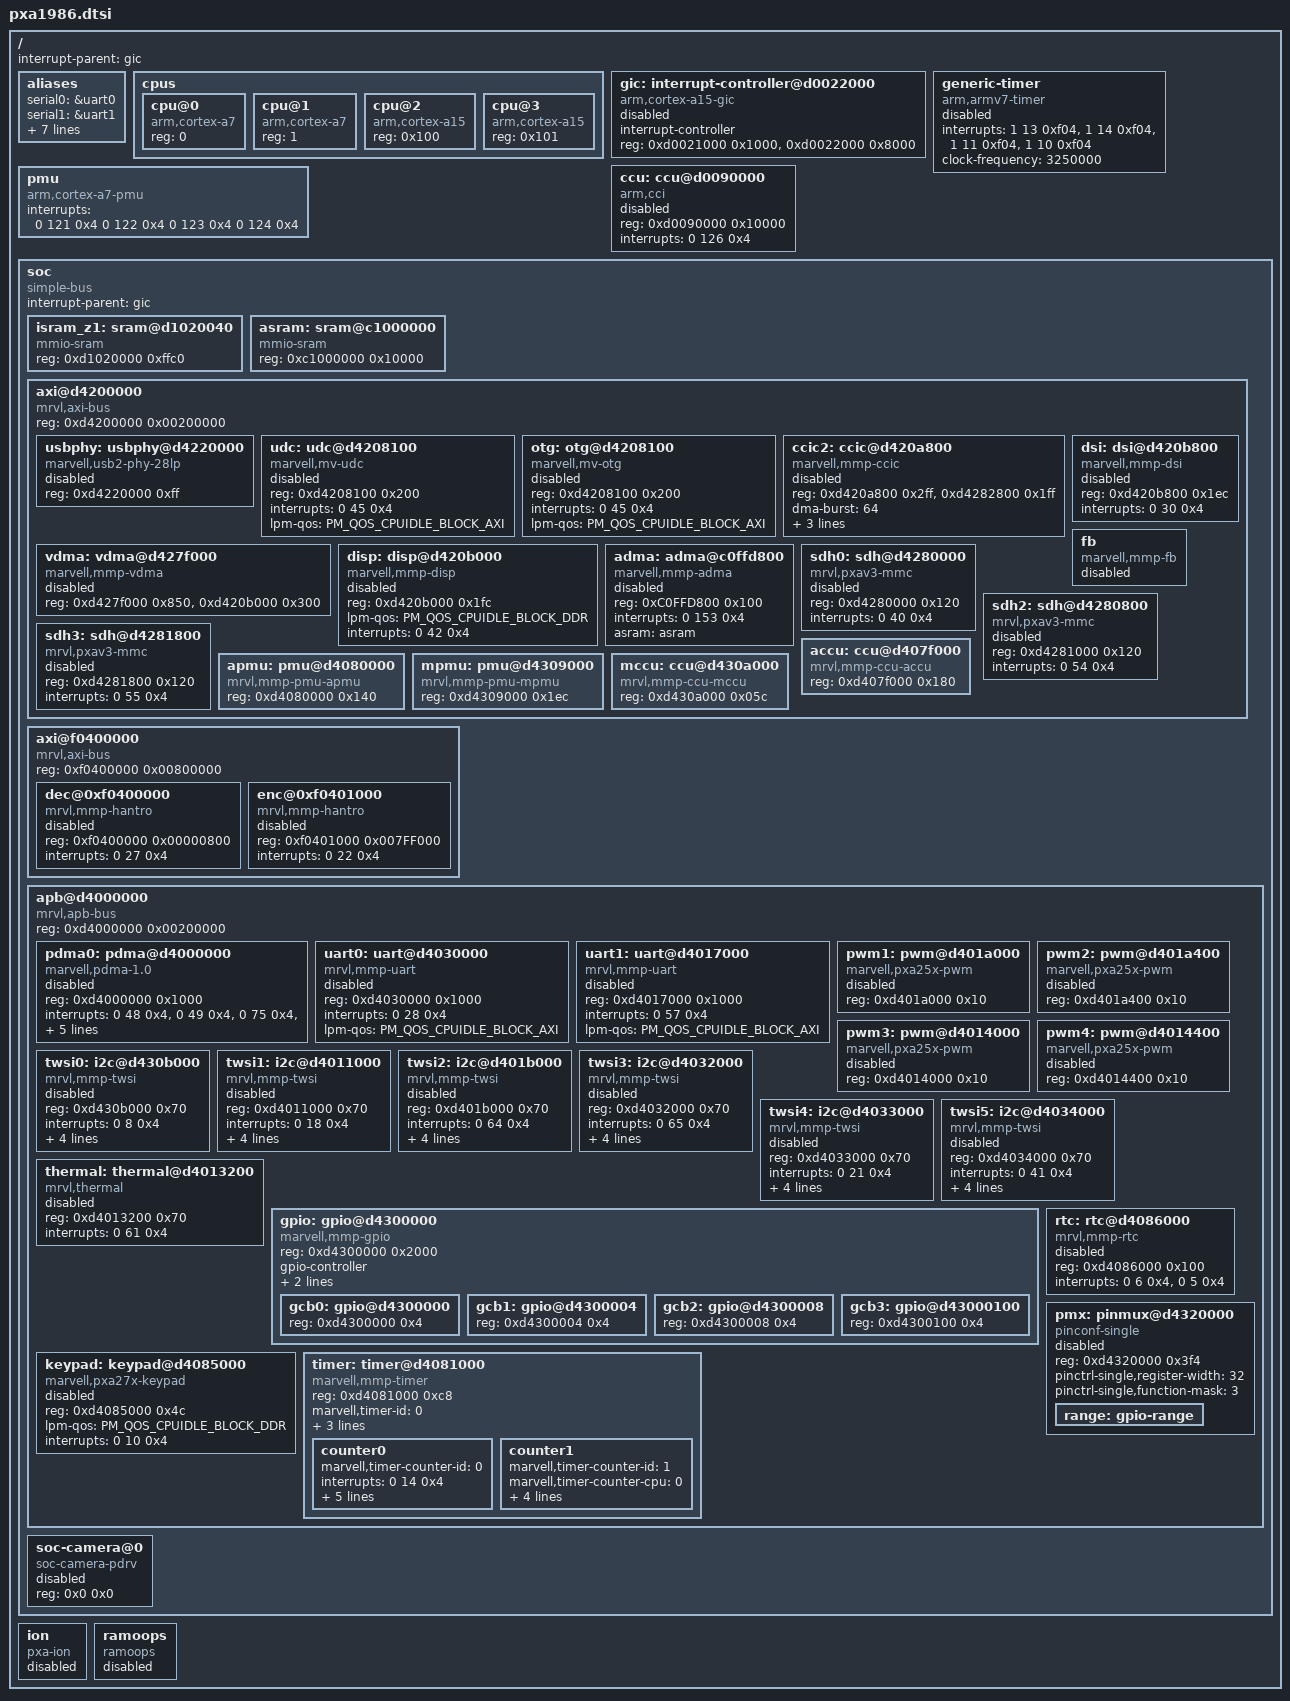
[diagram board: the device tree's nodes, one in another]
/*
 *  Copyright (C) 2013 Marvell Technology Group Ltd.
 *  Author: Chao Xie <chao.xie@marvell.com>
 *
 *  This program is free software; you can redistribute it and/or modify
 *  it under the terms of the GNU General Public License version 2 as
 *  publishhed by the Free Software Foundation.
 */

#include "skeleton.dtsi"
#include "eden-pinfunc.h"
#include "eden-pm.h"
#include <dt-bindings/interrupt-controller/irq.h>
#include <dt-bindings/usb/mv_usb_phy.h>

/ {
	interrupt-parent = <&gic>;

	aliases {
		serial0 = &uart0;
		serial1 = &uart1;
		i2c0 = &twsi0;
		i2c1 = &twsi1;
		i2c2 = &twsi2;
		i2c3 = &twsi3;
		i2c4 = &twsi4;
		i2c5 = &twsi5;
		mmp-camera1 = &ccic2;
	};

	cpus {
		#address-cells = <1>;
		#size-cells = <0>;

		cpu@0 {
			device_type = "cpu";
			compatible = "arm,cortex-a7";
			reg = <0>;
		};
		cpu@1 {
			device_type = "cpu";
			compatible = "arm,cortex-a7";
			reg = <1>;
		};
		cpu@2 {
			device_type = "cpu";
			compatible = "arm,cortex-a15";
			reg = <0x100>;
		};
		cpu@3 {
			device_type = "cpu";
			compatible = "arm,cortex-a15";
			reg = <0x101>;
		};
	};

	gic: interrupt-controller@d0022000 {
		compatible = "arm,cortex-a15-gic";
		interrupt-controller;
		#interrupt-cells = <3>;
		reg = <0xd0021000 0x1000>,
		      <0xd0022000 0x8000>;
		status = "disabled";
	};

	generic-timer {
		compatible = "arm,armv7-timer";
		/* PPI secure/nonsecure IRQ, active high level-sensitive */
		interrupts = <1 13 0xf04>,
					 <1 14 0xf04>,
					 <1 11 0xf04>,
					 <1 10 0xf04>;
		clock-frequency = <3250000>;
		status = "disabled";
	};

	ccu: ccu@d0090000 {
		compatible = "arm,cci";
		#address-cells = <1>;
		#size-cells = <1>;
		reg = <0xd0090000 0x10000>;
		interrupts = <0 126 0x4>;
		status = "disable";
	};

	pmu {
		compatible = "arm,cortex-a7-pmu";
		interrupts = <0 121 0x4
			      0 122 0x4
			      0 123 0x4
			      0 124 0x4>;
	};

	soc {
		#address-cells = <1>;
		#size-cells = <1>;
		compatible = "simple-bus";
		interrupt-parent = <&gic>;
		ranges;

		isram_z1: sram@d1020040 {
			compatible = "mmio-sram";
			reg = <0xd1020000 0xffc0>;	/* 64KB */
		};

		asram: sram@c1000000 {
			compatible = "mmio-sram";
			reg = <0xc1000000 0x10000>;	/* 64KB */
		};

		axi@d4200000 {	/* AXI */
			compatible = "mrvl,axi-bus", "simple-bus";
			#address-cells = <1>;
			#size-cells = <1>;
			reg = <0xd4200000 0x00200000>;
			ranges;

			usbphy: usbphy@d4220000 {
				compatible = "marvell,usb2-phy-28lp";
				reg = <0xd4220000 0xff>;
				status = "disabled";
			};

			udc: udc@d4208100 {
				compatible = "marvell,mv-udc";
				reg = <0xd4208100 0x200>;
				interrupts = <0 45 0x4>;
				lpm-qos = <PM_QOS_CPUIDLE_BLOCK_AXI>;
				status = "disabled";
			};

			otg: otg@d4208100 {
				compatible = "marvell,mv-otg";
				reg = <0xd4208100 0x200>;
				interrupts = <0 45 0x4>;
				lpm-qos = <PM_QOS_CPUIDLE_BLOCK_AXI>;
				status = "disabled";
			};

			ccic2: ccic@d420a800 {
				compatible = "marvell,mmp-ccic";
				reg = <0xd420a800 0x2ff>, <0xd4282800 0x1ff>;
				reg-names = "ccic-regs", "apmu-regs";
				dma-burst = <64>;
				mclk-src = <3>;
				mclk-div = <22>;
				interrupts = <0 43 0x4>;
				status = "disable";
			};

			dsi: dsi@d420b800 {
				compatible = "marvell,mmp-dsi";
				reg = <0xd420b800 0x1ec>;
				interrupts = <0 30 0x4>;
				status = "disabled";
			};

			vdma: vdma@d427f000 {
				compatible = "marvell,mmp-vdma";
				reg = <0xd427f000 0x850>, <0xd420b000 0x300>;
				status = "disabled";
			};

			disp: disp@d420b000 {
				compatible = "marvell,mmp-disp";
				reg = <0xd420b000 0x1fc>;
				lpm-qos = <PM_QOS_CPUIDLE_BLOCK_DDR>;
				interrupts = <0 42 0x4>;
				status = "disabled";
			};

			fb: fb {
				compatible = "marvell,mmp-fb";
				status = "disabled";
			};

/* FIXME */
			adma: adma@c0ffd800 {
				compatible = "marvell,mmp-adma";
				reg = <0xC0FFD800 0x100>;
				interrupts = <0 153 0x4>;
				#dma-cells = <1>;
				asram = <&asram>;
				status = "disabled";
			};

			sdh0: sdh@d4280000 {
					compatible = "mrvl,pxav3-mmc";
					reg = <0xd4280000 0x120>;
					interrupts = <0 40 0x4>;
					status = "disabled";
			 };

			sdh2: sdh@d4280800 {
					compatible = "mrvl,pxav3-mmc";
					reg = <0xd4281000 0x120>;
					interrupts = <0 54 0x4>;
					status = "disabled";
			};

			sdh3: sdh@d4281800 {
					compatible = "mrvl,pxav3-mmc";
					reg = <0xd4281800 0x120>;
					interrupts = <0 55 0x4>;
					status = "disabled";
			};

			apmu: pmu@d4080000 {
				compatible = "mrvl,mmp-pmu-apmu";
				reg = <0xd4080000 0x140>;
			};

			accu: ccu@d407f000 {
				compatible = "mrvl,mmp-ccu-accu";
				reg = <0xd407f000 0x180>;
			};

			mpmu: pmu@d4309000 {
				compatible = "mrvl,mmp-pmu-mpmu";
				reg = <0xd4309000 0x1ec>;
			};

			mccu: ccu@d430a000 {
				compatible = "mrvl,mmp-ccu-mccu";
				reg = <0xd430a000 0x05c>;
			};
		};

		axi@f0400000 {
			compatible = "mrvl,axi-bus", "simple-bus";
			#address-cells = <1>;
			#size-cells = <1>;
			reg = <0xf0400000 0x00800000>;
			ranges;

			dec@0xf0400000 {
				compatible = "mrvl,mmp-hantro";
				reg = <0xf0400000 0x00000800>;
				interrupts = <0 27 0x4>;
				status = "disabled";
			};

			enc@0xf0401000 {
				compatible = "mrvl,mmp-hantro";
				reg = <0xf0401000 0x007FF000>;
				interrupts = <0 22 0x4>;
				status = "disabled";
			};
		};

		apb@d4000000 {	/* APB */
			compatible = "mrvl,apb-bus", "simple-bus";
			#address-cells = <1>;
			#size-cells = <1>;
			reg = <0xd4000000 0x00200000>;
			ranges;

			pdma0: pdma@d4000000 {
				compatible = "marvell,pdma-1.0";
				reg = <0xd4000000 0x1000>;
				interrupts = <0 48 0x4>, <0 49 0x4>, <0 75 0x4>, <0 76 0x4>,
						<0 77 0x4>, <0 78 0x4>, <0 79 0x4>, <0 80 0x4>,
						<0 81 0x4>, <0 82 0x4>, <0 83 0x4>, <0 84 0x4>,
						<0 85 0x4>, <0 86 0x4>, <0 87 0x4>, <0 88 0x4>;
				#dma-cells= <2>;
				#dma-channels = <16>;
				status = "disabled";
			};

/* FIXME - enable when sound will be enabled */
#if 0
			sspa0: sspa@c0ffdc00 {
				compatible = "mrvl,mmp-sspa-dai";
				reg = <0xc0ffdc00 0x1000>;
				interrupts = <0 31 0x4>;
				dmas = <&adma 1
					&adma 0>;
				dma-names = "rx", "tx";
				asram = <&asram_z1>;
				platform_driver_name = "tdma_platform";
				status = "disabled";
			};
#endif

			uart0: uart@d4030000 {
				compatible = "mrvl,mmp-uart";
				reg = <0xd4030000 0x1000>;
				interrupts = <0 28 0x4>;
/* FIXME - no need pdma for now */
#if 0
				dmas = <&pdma0 0 1
					&pdma0 1 1>;
				dma-names = "rx", "tx";
#endif
				lpm-qos = <PM_QOS_CPUIDLE_BLOCK_AXI>;
				status = "disabled";
			};

			uart1: uart@d4017000 {
				compatible = "mrvl,mmp-uart";
				reg = <0xd4017000 0x1000>;
				interrupts = <0 57 0x4>;
/* FIXME - no need pdma for now */
#if 0
				dmas = <&pdma0 10 1
					&pdma0 11 1>;
				dma-names = "rx", "tx";
#endif
				lpm-qos = <PM_QOS_CPUIDLE_BLOCK_AXI>;
				status = "disabled";
			};

			pwm1: pwm@d401a000 {
				compatible = "marvell,pxa25x-pwm";
				reg = <0xd401a000 0x10>;
				#pwm-cells = <2>;
				status = "disabled";
			};

			pwm2: pwm@d401a400 {
				compatible = "marvell,pxa25x-pwm";
				reg = <0xd401a400 0x10>;
				#pwm-cells = <2>;
				status = "disabled";
			};

			pwm3: pwm@d4014000 {
				compatible = "marvell,pxa25x-pwm";
				reg = <0xd4014000 0x10>;
				#pwm-cells = <2>;
				status = "disabled";
			};

			pwm4: pwm@d4014400 {
				compatible = "marvell,pxa25x-pwm";
				reg = <0xd4014400 0x10>;
				#pwm-cells = <2>;
				status = "disabled";
			};

			twsi0: i2c@d430b000 {
				compatible = "mrvl,mmp-twsi";
				reg = <0xd430b000 0x70>;
				interrupts = <0 8 0x4>;
				#address-cells = <1>;
				#size-cells = <0>;
				lpm-qos = <PM_QOS_CPUIDLE_BLOCK_DDR>;
				mrvl,i2c-fast-mode;
				/*
				 *ilcr: fast mode b17~9=0x10, 400k
				 *      standard mode b8~0=0x9a, 100k
				 *iwcr: b5~0=b01010 recommended value from spec
				 */
				marvell,i2c-ilcr = <0x082C409a>;
				marvell,i2c-iwcr = <0x0000142a>;
				status = "disabled";
			};

			twsi1: i2c@d4011000 {
				compatible = "mrvl,mmp-twsi";
				reg = <0xd4011000 0x70>;
				interrupts = <0 18 0x4>;
				#address-cells = <1>;
				#size-cells = <0>;
				lpm-qos = <PM_QOS_CPUIDLE_BLOCK_DDR>;
				mrvl,i2c-fast-mode;
				marvell,i2c-ilcr = <0x082C489F>;
				marvell,i2c-iwcr = <0x0000142a>;
				status = "disabled";
			};

			twsi2: i2c@d401b000 {
				compatible = "mrvl,mmp-twsi";
				reg = <0xd401b000 0x70>;
				interrupts = <0 64 0x4>;
				#address-cells = <1>;
				#size-cells = <0>;
				lpm-qos = <PM_QOS_CPUIDLE_BLOCK_DDR>;
				mrvl,i2c-fast-mode;
				marvell,i2c-ilcr = <0x082C489F>;
				marvell,i2c-iwcr = <0x0000142a>;
				status = "disabled";
			};

			twsi3: i2c@d4032000 {
				compatible = "mrvl,mmp-twsi";
				reg = <0xd4032000 0x70>;
				interrupts = <0 65 0x4>;
				#address-cells = <1>;
				#size-cells = <0>;
				lpm-qos = <PM_QOS_CPUIDLE_BLOCK_DDR>;
				mrvl,i2c-fast-mode;
				marvell,i2c-ilcr = <0x082C489F>;
				marvell,i2c-iwcr = <0x0000142a>;
				status = "disabled";
			};

			twsi4: i2c@d4033000 {
				compatible = "mrvl,mmp-twsi";
				reg = <0xd4033000 0x70>;
				interrupts = <0 21 0x4>;
				#address-cells = <1>;
				#size-cells = <0>;
				lpm-qos = <PM_QOS_CPUIDLE_BLOCK_DDR>;
				mrvl,i2c-fast-mode;
				marvell,i2c-ilcr = <0x082C489F>;
				marvell,i2c-iwcr = <0x0000142a>;
				status = "disabled";
			};

			twsi5: i2c@d4034000 {
				compatible = "mrvl,mmp-twsi";
				reg = <0xd4034000 0x70>;
				interrupts = <0 41 0x4>;
				#address-cells = <1>;
				#size-cells = <0>;
				lpm-qos = <PM_QOS_CPUIDLE_BLOCK_DDR>;
				mrvl,i2c-fast-mode;
				marvell,i2c-ilcr = <0x082C489F>;
				marvell,i2c-iwcr = <0x0000142a>;
				status = "disabled";
			};

/* FIXME - add gpu thermals */
			thermal: thermal@d4013200 {
				compatible = "mrvl,thermal";
				reg = <0xd4013200 0x70>;
				interrupts = <0 61 0x4>;
				status = "disabled";
			};

			gpio: gpio@d4300000 {
				compatible = "marvell,mmp-gpio";
				#address-cells = <1>;
				#size-cells = <1>;
				reg = <0xd4300000 0x2000>;
				gpio-controller;
				#gpio-cells = <2>;
				interrupts = <0 24 0x4>;
				interrupt-names = "gpio_mux";
				interrupt-controller;
				#interrupt-cells = <2>;
				ranges;

				gcb0: gpio@d4300000 {
					reg = <0xd4300000 0x4>;
				};

				gcb1: gpio@d4300004 {
					reg = <0xd4300004 0x4>;
				};

				gcb2: gpio@d4300008 {
					reg = <0xd4300008 0x4>;
				};

				gcb3: gpio@d43000100 {
					reg = <0xd4300100 0x4>;
				};
			};

			keypad: keypad@d4085000 {
				compatible = "marvell,pxa27x-keypad";
				reg = <0xd4085000 0x4c>;
				lpm-qos = <PM_QOS_CPUIDLE_BLOCK_DDR>;
				interrupts = <0 10 0x4>;
				status = "disabled";
			};

			rtc: rtc@d4086000 {
				compatible = "mrvl,mmp-rtc";
				reg = <0xd4086000 0x100>;
				interrupts = <0 6 0x4>,<0 5 0x4>;
				interrupt-names = "rtc 1Hz", "rtc alarm";
				status = "disabled";
			};

			pmx: pinmux@d4320000 {
				compatible = "pinconf-single";
				reg = <0xd4320000 0x3f4>;
				#address-cells = <1>;
				#size-cells = <1>;
				#gpio-range-cells = <3>;
				ranges;
				status = "disabled";

				pinctrl-single,register-width = <32>;
				pinctrl-single,function-mask = <3>;

				range: gpio-range {
					#pinctrl-single,gpio-range-cells = <3>;
				};
			};

			timer: timer@d4081000 {
				compatible = "marvell,mmp-timer";
				reg = <0xd4081000 0xc8>;
				marvell,timer-id = <0>;
				marvell,timer-flag = <0>;
				marvell,timer-fc_freq = <3250000>;
				marvell,timer-apb_freq = <26000000>;

				counter0 {
					marvell,timer-counter-id = <0>;
					interrupts = <0 14 0x4>;
					marvell,timer-counter-cpu = <0>;
					marvell,timer-counter-cnt_freq = <32768>;
					marvell,timer-counter-usage = <2>;
					marvell,timer-counter-cnt_rating = <200>;
					marvell,timer-counter-mode = <1>;
				};

				counter1 {
					marvell,timer-counter-id = <1>;
					marvell,timer-counter-cpu = <0>;
					marvell,timer-counter-cnt_freq = <32768>;
					marvell,timer-counter-usage = <1>;
					marvell,timer-counter-cnt_rating = <200>;
					marvell,timer-counter-mode = <0>;
				};
			};
		};

		soc-camera@0 {
			compatible = "soc-camera-pdrv";
			status = "disabled";
			reg = <0x0 0x0>;
		};
	};

	ion {
		compatible = "pxa-ion";
		status = "disabled";
	};

	ramoops {
		compatible = "ramoops";
		status = "disabled";
	};

/* FIXME - add when vpu will be added */
#if 0
	dec-devfreq {
		compatible = "marvell,devfreq-vpu";
		reg = <0xf0400000 0x00000800>;
		status = "disabled";
	};

	enc-devfreq {
		compatible = "marvell,devfreq-vpu";
		reg = <0xf0400800 0x003ff800>;
		status = "disabled";
	};
#endif
};
